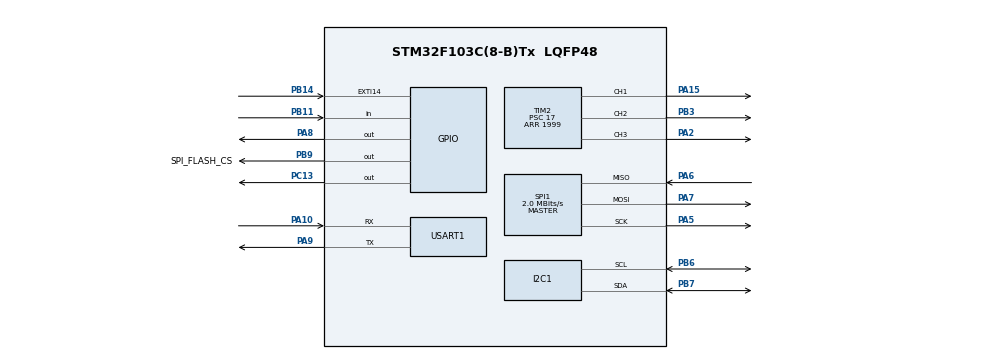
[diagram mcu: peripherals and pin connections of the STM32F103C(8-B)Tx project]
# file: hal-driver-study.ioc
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Dma.Request0=USART1_RX
Dma.Request1=USART1_TX
Dma.USART1_RX.0.Direction=DMA_PERIPH_TO_MEMORY
Dma.USART1_RX.0.Instance=DMA1_Channel5
Dma.USART1_RX.0.MemDataAlignment=DMA_MDATAALIGN_BYTE
Dma.USART1_RX.0.MemInc=DMA_MINC_ENABLE
Dma.USART1_RX.0.Mode=DMA_NORMAL
Dma.USART1_RX.0.PeriphDataAlignment=DMA_PDATAALIGN_BYTE
Dma.USART1_RX.0.PeriphInc=DMA_PINC_DISABLE
Dma.USART1_RX.0.Priority=DMA_PRIORITY_LOW
Dma.USART1_TX.1.Direction=DMA_MEMORY_TO_PERIPH
Dma.USART1_TX.1.Instance=DMA1_Channel4
Dma.USART1_TX.1.MemDataAlignment=DMA_MDATAALIGN_BYTE
Dma.USART1_TX.1.MemInc=DMA_MINC_ENABLE
Dma.USART1_TX.1.Mode=DMA_NORMAL
Dma.USART1_TX.1.PeriphDataAlignment=DMA_PDATAALIGN_BYTE
Dma.USART1_TX.1.PeriphInc=DMA_PINC_DISABLE
Dma.USART1_TX.1.Priority=DMA_PRIORITY_LOW
Mcu.Family=STM32F1
Mcu.Name=STM32F103C(8-B)Tx
Mcu.Package=LQFP48
NVIC.DMA1_Channel4_IRQn=true\:0\:0\:false\:true\:true\:1\:false\:true\:true
NVIC.DMA1_Channel5_IRQn=true\:0\:0\:false\:true\:true\:2\:false\:true\:true
NVIC.EXTI15_10_IRQn=true\:0\:0\:true\:false\:true\:true\:true\:true
NVIC.I2C1_ER_IRQn=true\:0\:0\:false\:false\:true\:true\:true\:true
NVIC.I2C1_EV_IRQn=true\:0\:0\:false\:false\:true\:true\:true\:true
NVIC.PriorityGroup=NVIC_PRIORITYGROUP_4
NVIC.SPI1_IRQn=true\:0\:0\:false\:false\:true\:true\:true\:true
NVIC.USART1_IRQn=true\:0\:0\:false\:true\:true\:3\:true\:true\:true
PA10.Mode=Asynchronous
PA10.Signal=USART1_RX
PA13.Mode=Serial_Wire
PA13.Signal=SYS_JTMS-SWDIO
PA14.Mode=Serial_Wire
PA14.Signal=SYS_JTCK-SWCLK
PA15.Signal=S_TIM2_CH1_ETR
PA2.Signal=S_TIM2_CH3
PA5.Mode=Full_Duplex_Master
PA5.Signal=SPI1_SCK
PA6.Mode=Full_Duplex_Master
PA6.Signal=SPI1_MISO
PA7.Mode=Full_Duplex_Master
PA7.Signal=SPI1_MOSI
PA8.Signal=GPIO_Output
PA9.Mode=Asynchronous
PA9.Signal=USART1_TX
PB11.Signal=GPIO_Input
PB14.GPIO_ModeDefaultEXTI=GPIO_MODE_IT_RISING_FALLING
PB14.Signal=GPXTI14
PB3.Signal=S_TIM2_CH2
PB6.Mode=I2C
PB6.Signal=I2C1_SCL
PB7.Mode=I2C
PB7.Signal=I2C1_SDA
PB9.GPIO_Label=SPI_FLASH_CS
PB9.GPIO_Speed=GPIO_SPEED_FREQ_HIGH
PB9.PinState=GPIO_PIN_SET
PB9.Signal=GPIO_Output
PC13-TAMPER-RTC.Signal=GPIO_Output
ProjectManager.HeapSize=0x200
ProjectManager.StackSize=0x400
ProjectManager.TargetToolchain=MDK-ARM V5.32
RCC.APB1Freq_Value=8000000
RCC.APB2Freq_Value=8000000
SH.S_TIM2_CH1_ETR.0=TIM2_CH1,PWM Generation1 CH1
SH.S_TIM2_CH2.0=TIM2_CH2,PWM Generation2 CH2
SH.S_TIM2_CH3.0=TIM2_CH3,PWM Generation3 CH3
SPI1.BaudRatePrescaler=SPI_BAUDRATEPRESCALER_4
SPI1.CalculateBaudRate=2.0 MBits/s
SPI1.Direction=SPI_DIRECTION_2LINES
SPI1.Mode=SPI_MODE_MASTER
SPI1.VirtualType=VM_MASTER
TIM2.AutoReloadPreload=TIM_AUTORELOAD_PRELOAD_ENABLE
TIM2.Channel-PWM\ Generation1\ CH1=TIM_CHANNEL_1
TIM2.Channel-PWM\ Generation2\ CH2=TIM_CHANNEL_2
TIM2.Channel-PWM\ Generation3\ CH3=TIM_CHANNEL_3
TIM2.OCPolarity_1=TIM_OCPOLARITY_LOW
TIM2.OCPolarity_2=TIM_OCPOLARITY_LOW
TIM2.OCPolarity_3=TIM_OCPOLARITY_LOW
TIM2.Period=1999
TIM2.Prescaler=17
USART1.VirtualMode=VM_ASYNC
board=custom

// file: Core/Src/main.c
/* USER CODE BEGIN Header */
/**
  ******************************************************************************
  * @file           : main.c
  * @brief          : Main program body
  ******************************************************************************
  * @attention
  *
  * Copyright (c) 2026 STMicroelectronics.
  * All rights reserved.
  *
  * This software is licensed under terms that can be found in the LICENSE file
  * in the root directory of this software component.
  * If no LICENSE file comes with this software, it is provided AS-IS.
  *
  ******************************************************************************
  */
/* USER CODE END Header */
#include "main.h"
#include "dma.h"
#include "i2c.h"
#include "spi.h"
#include "tim.h"
#include "usart.h"
#include "gpio.h"

/* USER CODE BEGIN Includes */
#include "app.h"
#include "app_uart.h"
/* USER CODE END Includes */

void SystemClock_Config(void);
static void MX_NVIC_Init(void);

int main(void)
{

  /* MCU Configuration--------------------------------------------------------*/

  /* Reset of all peripherals, Initializes the Flash interface and the Systick. */
  HAL_Init();

  /* Configure the system clock */
  SystemClock_Config();

  /* Initialize all configured peripherals */
  MX_GPIO_Init();
  MX_DMA_Init();
  MX_I2C1_Init();
  MX_USART1_UART_Init();
  MX_SPI1_Init();
  MX_TIM2_Init();

  /* Initialize interrupts */
  MX_NVIC_Init();
  /* USER CODE BEGIN 2 */
  app_uart_init();
  app_init();
  /* USER CODE END 2 */

  /* Infinite loop */
  /* USER CODE BEGIN WHILE */
  while (1)
  {
    app_poll();
    /* USER CODE END WHILE */

  }
}

void SystemClock_Config(void)
{
  RCC_OscInitTypeDef RCC_OscInitStruct = {0};
  RCC_ClkInitTypeDef RCC_ClkInitStruct = {0};

  /** Initializes the RCC Oscillators according to the specified parameters
  * in the RCC_OscInitTypeDef structure.
  */
  RCC_OscInitStruct.OscillatorType = RCC_OSCILLATORTYPE_HSI;
  RCC_OscInitStruct.HSIState = RCC_HSI_ON;
  RCC_OscInitStruct.HSICalibrationValue = RCC_HSICALIBRATION_DEFAULT;
  RCC_OscInitStruct.PLL.PLLState = RCC_PLL_NONE;
  if (HAL_RCC_OscConfig(&RCC_OscInitStruct) != HAL_OK)
  {
    Error_Handler();
  }

  /** Initializes the CPU, AHB and APB buses clocks
  */
  RCC_ClkInitStruct.ClockType = RCC_CLOCKTYPE_HCLK|RCC_CLOCKTYPE_SYSCLK
                              |RCC_CLOCKTYPE_PCLK1|RCC_CLOCKTYPE_PCLK2;
  RCC_ClkInitStruct.SYSCLKSource = RCC_SYSCLKSOURCE_HSI;
  RCC_ClkInitStruct.AHBCLKDivider = RCC_SYSCLK_DIV1;
  RCC_ClkInitStruct.APB1CLKDivider = RCC_HCLK_DIV1;
  RCC_ClkInitStruct.APB2CLKDivider = RCC_HCLK_DIV1;

  if (HAL_RCC_ClockConfig(&RCC_ClkInitStruct, FLASH_LATENCY_0) != HAL_OK)
  {
    Error_Handler();
  }
}

/**
  * @brief NVIC Configuration.
  * @retval None
  */
static void MX_NVIC_Init(void)
{
  /* DMA1_Channel4_IRQn interrupt configuration */
  HAL_NVIC_SetPriority(DMA1_Channel4_IRQn, 0, 0);
  HAL_NVIC_EnableIRQ(DMA1_Channel4_IRQn);
  /* DMA1_Channel5_IRQn interrupt configuration */
  HAL_NVIC_SetPriority(DMA1_Channel5_IRQn, 0, 0);
  HAL_NVIC_EnableIRQ(DMA1_Channel5_IRQn);
  /* USART1_IRQn interrupt configuration */
  HAL_NVIC_SetPriority(USART1_IRQn, 0, 0);
  HAL_NVIC_EnableIRQ(USART1_IRQn);
}

/* USER CODE BEGIN 4 */

void HAL_GPIO_EXTI_Callback(uint16_t GPIO_Pin)
{
	if (GPIO_Pin == KEY_GPIO_Pin) {
		app_on_key_exti();
	}
}

/* USER CODE END 4 */

void Error_Handler(void)
{
  __disable_irq();
  while (1)
  {
  }
}
